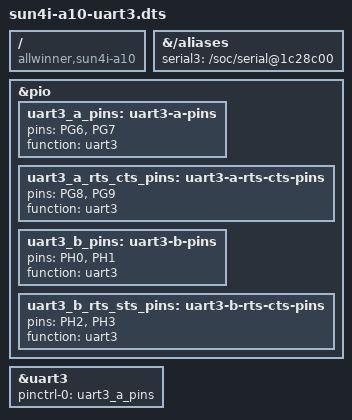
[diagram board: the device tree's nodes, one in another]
/dts-v1/;
/plugin/;

/ {
	compatible = "allwinner,sun4i-a10";

	fragment@0 {
		target-path = "/aliases";
		__overlay__ {
			serial3 = "/soc/serial@1c28c00";
		};
	};

	fragment@1 {
		target = <&pio>;
		__overlay__ {
			uart3_a_pins: uart3-a-pins {
				pins = "PG6", "PG7";
				function = "uart3";
			};

			uart3_a_rts_cts_pins: uart3-a-rts-cts-pins {
				pins = "PG8", "PG9";
				function = "uart3";
			};

			uart3_b_pins: uart3-b-pins {
				pins = "PH0", "PH1";
				function = "uart3";
			};

			uart3_b_rts_sts_pins: uart3-b-rts-cts-pins {
				pins = "PH2", "PH3";
				function = "uart3";
			};
		};
	};

	fragment@2 {
		target = <&uart3>;
		 __overlay__ {
			pinctrl-names = "default";
			pinctrl-0 = <&uart3_a_pins>;
			status = "okay";
		};
	};
};
